# Scan_Interface_1 register map
Vendor: Texas Instruments
Peripheral module from a debugger description file (folder msp430).
Registers are 16-bit, access not given, no defined reset value unless marked. A register's access mark holds for its fields unless they carry their own. Offsets are as the file gives them; lines under a group give offsets from that group; [hi:lo] are bit positions; {n}, {i} and the like mark numbered series; 'fields as' and 'values as' point back to an identical list; <NAME> marks a mode.

## Scan_Interface
0x1B0 SIFDEBUG — SIF
0x1B2 SIFCNT — SIF
0x1B4 SIFPSMV — SIF
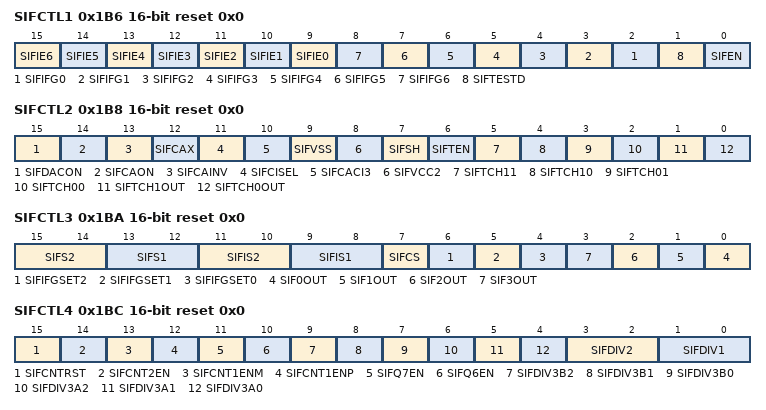
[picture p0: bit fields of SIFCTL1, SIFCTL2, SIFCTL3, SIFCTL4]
0x1B6 SIFCTL1 rw reset 0x0 — SIF
  [n+9] SIFIE{n} (n=0..6) — SIF Interrupt Enable {n}
  [n+2] SIFIFG{n} (n=0..6) — SIF Interrupt Flag {n}
  [1] SIFTESTD — SIF 0:Normal / 1:Test Mode
  [0] SIFEN — SIF Enable
0x1B8 SIFCTL2 rw reset 0x0 — SIF
  [15] SIFDACON — SIF Switch DAC on
  [14] SIFCAON — SIF Switch CA on
  [13] SIFCAINV — SIF Invert CA Output 0:off/1:on
  [12] SIFCAX — SIF Select CA Source
  [11] SIFCISEL — SIF Comparator Input Select
  [10] SIFCACI3 — SIF Selection of SIFCI3
  [9] SIFVSS — SIF Select Terminal for sample Cap.
  [8] SIFVCC2 — SIF VCC/2 Generator off/on
  [7] SIFSH — SIF Sample on/off
  [6] SIFTEN — SIF Enable Transistors
  [5] SIFTCH11 — SIF 2. Channel select 1
  [4] SIFTCH10 — SIF 2. Channel select 0
  [3] SIFTCH01 — SIF 1. Channel select 1
  [2] SIFTCH00 — SIF 1. Channel select 0
  [1] SIFTCH1OUT — SIF TCH1 result
  [0] SIFTCH0OUT — SIF TCH0 result
0x1BA SIFCTL3 rw reset 0x0 — SIF
  [15:14] SIFS2 — SIF S2 Source Select 0
    {v}=SIF S2 Source : SIF{v}OUT (v=0..3)
  [13:12] SIFS1 — SIF S1 Source Select 0
    {v}=SIF S1 Source : SIF{v}OUT (v=0..3)
  [11:10] SIFIS2 — SIF SIFIFG4 Int.Flag Source 0
    0=SIF SIFIFG4 set with each count of SIFCNT2; 1=SIF SIFIFG4 set if (SIFCNT2 mod 4)=0; 2=SIF SIFIFG4 set if (SIFCNT2 mod 64)=0; 3=SIF SIFIFG4 set if SIFCNT2 rolls over
  [9:8] SIFIS1 — SIF SIFIFG3 Int.Flag Source 0
    0=SIF SIFIFG3 set with each count of SIFCNT1; 1=SIF SIFIFG3 set if (SIFCNT1 mod 4)=0; 2=SIF SIFIFG3 set if (SIFCNT1 mod 64)=0; 3=SIF SIFIFG3 set if SIFCNT1 rolls over
  [7] SIFCS — SIF Capture Select
  [6] SIFIFGSET2 — SIF SIFIFG2 level select
  [5] SIFIFGSET1 — SIF SIFIFG1 level select
  [4] SIFIFGSET0 — SIF SIFIFG0 level select
  [n] SIF{n}OUT (n=0..3) — SIF Sensor {n} Out
0x1BC SIFCTL4 rw reset 0x0 — SIF
  [15] SIFCNTRST — SIF Enable Counter Reset on Read
  [14] SIFCNT2EN — SIF Enable SIFCNT2 count
  [13] SIFCNT1ENM — SIF Enable SIFCNT1 down count
  [12] SIFCNT1ENP — SIF Enable SIFCNT1 up count
  [11] SIFQ7EN — SIF Feedback 7 Enable
  [10] SIFQ6EN — SIF Feedback 6 Enable
  [9] SIFDIV3B2 — SIF Clock Divider 3.5
  [8] SIFDIV3B1 — SIF Clock Divider 3.4
  [7] SIFDIV3B0 — SIF Clock Divider 3.3
  [6] SIFDIV3A2 — SIF Clock Divider 3.2
  [5] SIFDIV3A1 — SIF Clock Divider 3.1
  [4] SIFDIV3A0 — SIF Clock Divider 3.0
  [3:2] SIFDIV2 — SIF Clock Divider 2.0
  [1:0] SIFDIV1 — SIF Clock Divider 1.0
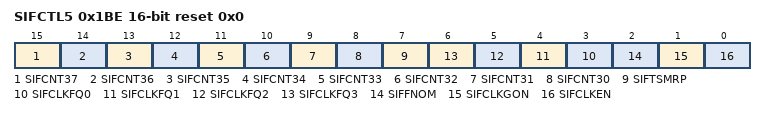
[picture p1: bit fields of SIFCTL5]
0x1BE SIFCTL5 rw reset 0x0 — SIF
  [15] SIFCNT37 — SIF Counter 3.7
  [14] SIFCNT36 — SIF Counter 3.6
  [13] SIFCNT35 — SIF Counter 3.5
  [12] SIFCNT34 — SIF Counter 3.4
  [11] SIFCNT33 — SIF Counter 3.3
  [10] SIFCNT32 — SIF Counter 3.2
  [9] SIFCNT31 — SIF Counter 3.1
  [8] SIFCNT30 — SIF Counter 3.0
  [7] SIFTSMRP — SIF Timing State Machine Repeat mode
  [n+3] SIFCLKFQ{n} (n=0..3) — SIF Clock Generator frequency adjust {n}
  [2] SIFFNOM — SIF Select Nominal Frequ. 0:4MHz / 1:1MHz
  [1] SIFCLKGON — SIF Switch SIFCLKG on
  [0] SIFCLKEN — SIF 0:SMCLK for SIFCLK / 1:SIFCLKG for SIFCLK
{0x1C0+2i} SIFDACR{i} (i=0..7) — SIF
{0x1D0+2i} SIFTSM{i} (i=0..23) — SIF
